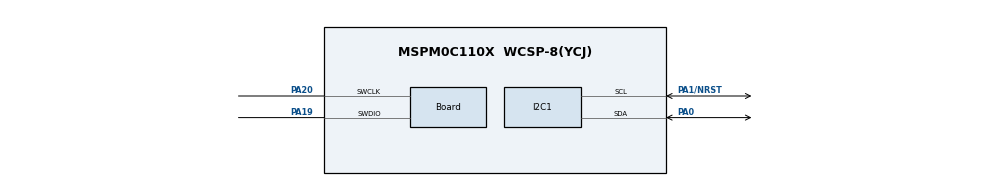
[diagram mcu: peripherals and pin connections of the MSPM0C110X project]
/**
 * @cliArgs --device "MSPM0C110X" --part "Default" --package "WCSP-8(YCJ)" --product "mspm0_sdk@2.04.00.06"
 * @versions {"tool":"1.23.0+4000"}
 */

/**
 * Import the modules used in this configuration.
 */
const GPIO   = scripting.addModule("/ti/driverlib/GPIO", {}, false);
const GPIO1  = GPIO.addInstance();
const I2C    = scripting.addModule("/ti/driverlib/I2C", {}, false);
const I2C1   = I2C.addInstance();
const SYSCTL = scripting.addModule("/ti/driverlib/SYSCTL");

/**
 * Write custom configuration values to the imported modules.
 */
GPIO1.$name                          = "GPIO_LEDS";
GPIO1.associatedPins.create(2);
GPIO1.associatedPins[0].$name        = "USER_LED_1";
GPIO1.associatedPins[0].initialValue = "SET";
GPIO1.associatedPins[0].assignedPin  = "24";
GPIO1.associatedPins[1].$name        = "USER_TEST";
GPIO1.associatedPins[1].initialValue = "SET";
GPIO1.associatedPins[1].assignedPin  = "27";

const Board                       = scripting.addModule("/ti/driverlib/Board", {}, false);
Board.peripheral.$assign          = "DEBUGSS";
Board.peripheral.swclkPin.$assign = "PA20";
Board.peripheral.swdioPin.$assign = "PA19";

I2C1.$name                     = "I2C_0";
I2C1.basicEnableController     = true;
I2C1.peripheral.$assign        = "I2C0";
I2C1.peripheral.sdaPin.$assign = "PA0";
I2C1.peripheral.sclPin.$assign = "PA1/NRST";
I2C1.sdaPinConfig.$name        = "ti_driverlib_gpio_GPIOPinGeneric0";
I2C1.sclPinConfig.$name        = "ti_driverlib_gpio_GPIOPinGeneric1";

SYSCTL.disableNRSTPin     = true;
SYSCTL.peripheral.$assign = "SYSCTL";

const ProjectConfig              = scripting.addModule("/ti/project_config/ProjectConfig", {}, false);
ProjectConfig.migrationCondition = true;

/**
 * Pinmux solution for unlocked pins/peripherals. This ensures that minor changes to the automatic solver in a future
 * version of the tool will not impact the pinmux you originally saw.  These lines can be completely deleted in order to
 * re-solve from scratch.
 */
GPIO1.associatedPins[0].pin.$suggestSolution = "PA24";
GPIO1.associatedPins[1].pin.$suggestSolution = "PA27";
